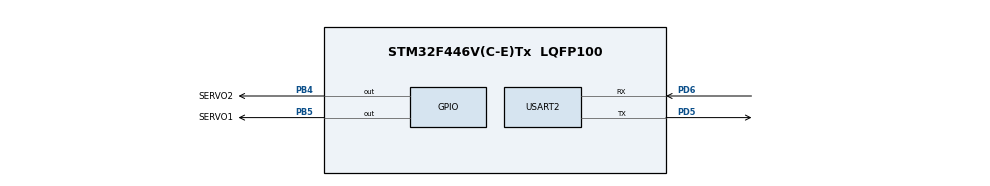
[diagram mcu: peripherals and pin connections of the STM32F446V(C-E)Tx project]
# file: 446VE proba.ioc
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Mcu.Family=STM32F4
Mcu.Name=STM32F446V(C-E)Tx
Mcu.Package=LQFP100
NVIC.PriorityGroup=NVIC_PRIORITYGROUP_4
PA13.Mode=Serial_Wire
PA13.Signal=SYS_JTMS-SWDIO
PA14.Mode=Serial_Wire
PA14.Signal=SYS_JTCK-SWCLK
PB3.Signal=SYS_JTDO-SWO
PB4.GPIO_Label=SERVO2
PB4.GPIO_PuPd=GPIO_PULLUP
PB4.Signal=GPIO_Output
PB5.GPIO_Label=SERVO1
PB5.GPIO_PuPd=GPIO_PULLUP
PB5.Signal=GPIO_Output
PD5.Mode=Asynchronous
PD5.Signal=USART2_TX
PD6.Mode=Asynchronous
PD6.Signal=USART2_RX
ProjectManager.HeapSize=0x200
ProjectManager.StackSize=0x400
ProjectManager.TargetToolchain=TrueSTUDIO
RCC.CortexFreq_Value=16000000
RCC.USBFreq_Value=96000000
RCC.VCOOutputFreq_Value=192000000
USART2.VirtualMode=VM_ASYNC
board=custom

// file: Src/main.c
/* USER CODE BEGIN Header */
/**
  ******************************************************************************
  * @file           : main.c
  * @brief          : Main program body
  ******************************************************************************
  ** This notice applies to any and all portions of this file
  * that are not between comment pairs USER CODE BEGIN and
  * USER CODE END. Other portions of this file, whether
  * inserted by the user or by software development tools
  * are owned by their respective copyright owners.
  *
  * COPYRIGHT(c) 2019 STMicroelectronics
  *
  * Redistribution and use in source and binary forms, with or without modification,
  * are permitted provided that the following conditions are met:
  *   1. Redistributions of source code must retain the above copyright notice,
  *      this list of conditions and the following disclaimer.
  *   2. Redistributions in binary form must reproduce the above copyright notice,
  *      this list of conditions and the following disclaimer in the documentation
  *      and/or other materials provided with the distribution.
  *   3. Neither the name of STMicroelectronics nor the names of its contributors
  *      may be used to endorse or promote products derived from this software
  *      without specific prior written permission.
  *
  * THIS SOFTWARE IS PROVIDED BY THE COPYRIGHT HOLDERS AND CONTRIBUTORS "AS IS"
  * AND ANY EXPRESS OR IMPLIED WARRANTIES, INCLUDING, BUT NOT LIMITED TO, THE
  * IMPLIED WARRANTIES OF MERCHANTABILITY AND FITNESS FOR A PARTICULAR PURPOSE ARE
  * DISCLAIMED. IN NO EVENT SHALL THE COPYRIGHT HOLDER OR CONTRIBUTORS BE LIABLE
  * FOR ANY DIRECT, INDIRECT, INCIDENTAL, SPECIAL, EXEMPLARY, OR CONSEQUENTIAL
  * DAMAGES (INCLUDING, BUT NOT LIMITED TO, PROCUREMENT OF SUBSTITUTE GOODS OR
  * SERVICES; LOSS OF USE, DATA, OR PROFITS; OR BUSINESS INTERRUPTION) HOWEVER
  * CAUSED AND ON ANY THEORY OF LIABILITY, WHETHER IN CONTRACT, STRICT LIABILITY,
  * OR TORT (INCLUDING NEGLIGENCE OR OTHERWISE) ARISING IN ANY WAY OUT OF THE USE
  * OF THIS SOFTWARE, EVEN IF ADVISED OF THE POSSIBILITY OF SUCH DAMAGE.
  *
  ******************************************************************************
  */
/* USER CODE END Header */

#include "main.h"

UART_HandleTypeDef huart2;

void SystemClock_Config(void);
static void MX_GPIO_Init(void);
static void MX_USART2_UART_Init(void);

int main(void)
{

  /* MCU Configuration--------------------------------------------------------*/

  /* Reset of all peripherals, Initializes the Flash interface and the Systick. */
  HAL_Init();

  /* Configure the system clock */
  SystemClock_Config();

  /* Initialize all configured peripherals */
  MX_GPIO_Init();
  MX_USART2_UART_Init();

  /* Infinite loop */
  /* USER CODE BEGIN WHILE */
  while (1)
  {
  	HAL_Delay(3000);
  	HAL_GPIO_TogglePin(SERVO1_GPIO_Port, SERVO1_Pin);
  	HAL_GPIO_TogglePin(SERVO2_GPIO_Port, SERVO2_Pin);

    /* USER CODE END WHILE */

  }
}

void SystemClock_Config(void)
{
  RCC_OscInitTypeDef RCC_OscInitStruct = {0};
  RCC_ClkInitTypeDef RCC_ClkInitStruct = {0};

  /**Configure the main internal regulator output voltage
  */
  __HAL_RCC_PWR_CLK_ENABLE();
  __HAL_PWR_VOLTAGESCALING_CONFIG(PWR_REGULATOR_VOLTAGE_SCALE3);
  /**Initializes the CPU, AHB and APB busses clocks
  */
  RCC_OscInitStruct.OscillatorType = RCC_OSCILLATORTYPE_HSI;
  RCC_OscInitStruct.HSIState = RCC_HSI_ON;
  RCC_OscInitStruct.HSICalibrationValue = RCC_HSICALIBRATION_DEFAULT;
  RCC_OscInitStruct.PLL.PLLState = RCC_PLL_NONE;
  if (HAL_RCC_OscConfig(&RCC_OscInitStruct) != HAL_OK)
  {
    Error_Handler();
  }
  /**Initializes the CPU, AHB and APB busses clocks
  */
  RCC_ClkInitStruct.ClockType = RCC_CLOCKTYPE_HCLK|RCC_CLOCKTYPE_SYSCLK
                              |RCC_CLOCKTYPE_PCLK1|RCC_CLOCKTYPE_PCLK2;
  RCC_ClkInitStruct.SYSCLKSource = RCC_SYSCLKSOURCE_HSI;
  RCC_ClkInitStruct.AHBCLKDivider = RCC_SYSCLK_DIV1;
  RCC_ClkInitStruct.APB1CLKDivider = RCC_HCLK_DIV1;
  RCC_ClkInitStruct.APB2CLKDivider = RCC_HCLK_DIV1;

  if (HAL_RCC_ClockConfig(&RCC_ClkInitStruct, FLASH_LATENCY_0) != HAL_OK)
  {
    Error_Handler();
  }
}

static void MX_USART2_UART_Init(void)
{

  huart2.Instance = USART2;
  huart2.Init.BaudRate = 115200;
  huart2.Init.WordLength = UART_WORDLENGTH_8B;
  huart2.Init.StopBits = UART_STOPBITS_1;
  huart2.Init.Parity = UART_PARITY_NONE;
  huart2.Init.Mode = UART_MODE_TX_RX;
  huart2.Init.HwFlowCtl = UART_HWCONTROL_NONE;
  huart2.Init.OverSampling = UART_OVERSAMPLING_16;
  if (HAL_UART_Init(&huart2) != HAL_OK)
  {
    Error_Handler();
  }

}

static void MX_GPIO_Init(void)
{
  GPIO_InitTypeDef GPIO_InitStruct = {0};

  /* GPIO Ports Clock Enable */
  __HAL_RCC_GPIOA_CLK_ENABLE();
  __HAL_RCC_GPIOD_CLK_ENABLE();
  __HAL_RCC_GPIOB_CLK_ENABLE();

  /*Configure GPIO pin Output Level */
  HAL_GPIO_WritePin(GPIOB, SERVO2_Pin|SERVO1_Pin, GPIO_PIN_RESET);

  /*Configure GPIO pins : SERVO2_Pin SERVO1_Pin */
  GPIO_InitStruct.Pin = SERVO2_Pin|SERVO1_Pin;
  GPIO_InitStruct.Mode = GPIO_MODE_OUTPUT_PP;
  GPIO_InitStruct.Pull = GPIO_PULLUP;
  GPIO_InitStruct.Speed = GPIO_SPEED_FREQ_LOW;
  HAL_GPIO_Init(GPIOB, &GPIO_InitStruct);

}

void Error_Handler(void)
{
}

/************************ (C) COPYRIGHT STMicroelectronics *****END OF FILE****/
